# SN32F290 register map
Vendor: SONIX; File version: 2026.10.03
CPU: CM0 r0p0, little endian, no MPU, no FPU, 2 interrupt priority bits
Registers are 32-bit, read-write, reset 0x0 unless marked. A register's access mark holds for its fields unless they carry their own. Offsets are from the block's base; [hi:lo] are bit positions; {n}, {i} and the like mark numbered series; 'fields as' and 'values as' point back to an identical list.

## SN_USB — Universal Serial Bus Full Speed Device Interface (USB)
Base 0x4005C000
0x00 INTEN (reset mask 0xF0000007F) — Offset:0x00 USB Interrupt Enable Register
  [62:31] BUS_IE — Bus Event Interrupt Enable
    0=Disable_434 (Disable BUS event interrupt); 1=Enable_145 (Enable Bus event interrupt)
  [60:30] USB_SOF_IE — USB SOF Interrupt Enable
    0=Disable_434 (Disable USB SOF interrupt); 1=Enable_145 (Enable USB SOF interrupt)
  [58:29] USB_IE — USB Event Interrupt Enable
    0=Disable_434 (Disable USB event interrupt); 1=Enable_145 (Enable USB event interrupt)
  [56:28] BUSWK_IE — USB Bus Wake Up Interrupt Enable
    0=Disable_434 (Disable Wake Up event interrupt); 1=Enable_145 (Enable Wake Up event interrupt)
  [12:6] EPN_ACK_EN — EPN ACK Interrupt Enable
    0=Disable_434 (Disable EP1~4 ACK interrupt function); 1=Enable_145 (Enable EP1~4 ACK interrupt function)
  [2n-2:n-1] EP{n}_NAK_EN (n=2..6) — EP{n} NAK Interrupt Enable
    0=Disable_434 (Disable EP{n} NAK interrupt function); 1=Enable_145 (Enable EP{n} NAK interrupt function)
  [0] EP1_NAK_EN — EP1 NAK Interrupt Enable
    0=Disable_434 (Disable EP1 NAK interrupt function); 1=Enable_145 (Enable EP1 NAK interrupt function)
0x04 INSTS ro (reset mask 0xE7FE3F3F) — Offset:0x04 USB Interrupt Event Status Register
  [62:31] BUS_RESET — USB Bus Reset signal flag
    0=V_0_164 (No bus reset signal is detected); 1=V_1_374 (Bus reset signal is detected)
  [60:30] BUS_SUSPEND — USB Bus Suspend signal flag
    0=V_0_164 (No bus suspend is detected); 1=V_1_374 (Bus suspend is detected)
  [58:29] BUS_RESUME — USB Bus Resume signal flag
    0=V_0_164 (No bus resume signal is detected); 1=V_1_374 (Bus resume signal from suspend mode is detected)
  [52:26] USB_SOF — USB SOF packet received flag
    0=V_0_164 (No USB SOF packet); 1=V_1_374 (USB SOF packet is received)
  [50:25] BUS_WAKEUP — Bus Wakeup Flag
    0=V_0_164 (No wakeup from suspend mode); 1=V_1_374 (Wakeup from suspend mode)
  [48:24] EP0_PRESETUP — EP0 Setup Token Packet Flag
    0=V_0_164 (No EP0 Setup token packet); 1=V_1_374 (EP0 Setup token packet is received)
  [46:23] EP0_SETUP — EP0 Setup Transaction Flag
    0=V_0_164 (No EP0 Setup transaction); 1=V_1_374 (EP0 Setup transaction is completed)
  [44:22] EP0_IN — EP0 IN ACK Transaction Flag
    0=V_0_164 (No EP0 IN Transaction); 1=V_1_374 (EP0 IN Transaction is completed)
  [42:21] EP0_OUT — EP0 OUT ACK Transaction Flag
    0=V_0_164 (No EP0 OUT ACK transaction); 1=V_1_374 (EP0 OUT ACK transaction is completed)
  [40:20] EP0_IN_STALL — EP0 IN STALL Transaction is completed
    0=V_0_164 (No EP0 IN STALL transaction); 1=V_1_374 (EP0 IN STALL transaction is completed)
  [38:19] EP0_OUT_STALL — EP0 OUT STALL transaction
    0=V_0_164 (No EP0 OUT STALL transaction); 1=V_1_374 (EP0 OUT STALL transaction is completed)
  [36:18] ERR_SETUP — Wrong Setup data received
    0=V_0_164 (Normal 8-byte Setup DATA0 is received); 1=V_1_374 (Setup data is not 8-byte or is not DATA0)
  [34:17] ERR_TIMEOUT — Timeout Status
    0=V_0_164 (No time out); 1=V_1_374 (Bus no any response more than 18 bits time)
  [2n+14:n+7] EP{n}_ACK (n=1..6) — Endpoint {n} ACK transaction flag
    0=V_0_164 (No EP{n} ACK transacation); 1=V_1_374 (EP{n} ACK transaction completes)
  [2n-2:n-1] EP{n}_NAK (n=2..6) — Endpoint {n} NAK transaction flag
    0=V_0_164 (No EP{n} NAK transacation); 1=V_1_374 (EP{n} NAK transaction completes)
  [0] EP1_NAK — Endpoint 1 NAK transaction flag
    0=V_0_164 (No EP1 NAK transacation); 1=V_1_374 (EP1 NAK transaction completes)
0x08 INSTSC wo (reset mask 0xA7FE3F3F) — Offset:0x08 USB Interrupt Event Status Clear Register
  [62:31] BUS_RESETC — USB Bus Reset clear bit
    0=No_effect_200; 1=Clear_V_150 (Clear BUS_RESET bit)
  [58:29] BUS_RESUMEC — USB Bus Resume clear bit
    0=No_effect_200; 1=Clear_V_150 (Clear BUS_RESUME bit)
  [52:26] USB_SOFC — USB SOF clear bit
    0=No_effect_200; 1=Clear_V_150 (Clear USB_SOF bit)
  [50:25] BUS_WAKEUPC — Bus Wakeup clear bit
    0=No_effect_200; 1=Clear_V_150 (Clear BUS_WAKEUP bit)
  [48:24] EP0_PRESETUPC — EP0 PRESETUP clear bit
    0=No_effect_200; 1=Clear_V_150 (Clear EP0_PRESETUP bit)
  [46:23] EP0_SETUPC — EP0 SETUP clear bit
    0=No_effect_200; 1=Clear_V_150 (Clear EP0_SETUP bit)
  [44:22] EP0_INC — EP0 IN clear bit
    0=No_effect_200; 1=Clear_V_150 (Clear EP0_IN bit)
  [42:21] EP0_OUTC — EP0 OUT clear bit
    0=No_effect_200; 1=Clear_V_150 (Clear EP0_OUT bit)
  [40:20] EP0_IN_STALLC — EP0 IN STALL clear bit
    0=No_effect_200; 1=Clear_V_150 (Clear EP0_IN_STALL bit)
  [38:19] EP0_OUT_STALLC — EP0 OUT STALL clear bit
    0=No_effect_200; 1=Clear_V_150 (Clear EP0_OUT_STALL bit)
  [36:18] ERR_SETUPC — Error Setup clear bit
    0=No_effect_200; 1=Clear_V_150 (Clear ERR_SETUP bit)
  [34:17] ERR_TIMEOUTC — Timeout Error clear bit
    0=No_effect_200; 1=Clear_V_150 (Clear ERR_TIMEOUT bit)
  [2n+14:n+7] EP{n}_ACKC (n=1..6) — EP{n} ACK clear bit
    0=No_effect_200; 1=Clear_V_150 (Clear EP{n}_ACK bit)
  [2n-2:n-1] EP{n}_NAKC (n=2..6) — EP{n} NAK clear bit
    0=No_effect_200; 1=Clear_V_150 (Clear EP{n}_NAK bit)
  [0] EP1_NAKC — EP1 NAK clear bit
    0=No_effect_200; 1=Clear_V_150 (Clear EP1_NAK bit)
0x0C ADDR — Offset:0x0C USB Device Address Register
  [6:0] UADDR — USB device's address
0x10 CFG (reset mask 0xFC00003F) — Offset:0x10 USB Configuration Register
  [62:31] VREG33_EN — Enable the internal VREG33 ouput
    0=Disable_434 (Disable VREG33 ouput); 1=Enable_145 (Enable VREG33 ouput)
  [60:30] PHY_EN — PHY Transceiver Function Enable
    0=Disable_434 (Disable PHY transceiver function); 1=Enable_145 (Enable PHY transceiver function)
  [58:29] DPPU_EN — Enable internal D+ 1.5k pull-up resistor
    0=Disable_434 (Disable internal D+ pull-up resistor); 1=Enable_145 (Enable internal D+ pull-up resistor)
  [56:28] SIE_EN — USB Serial Interface Engine Enable
    0=Disable_434 (Disable USB SIE function); 1=Enable_145 (Enable USB SIE function)
  [54:27] ESD_EN — Enable USB anti-ESD protection
    0=Disable_434 (Disable anti-ESD protection); 1=Enable_145 (Enable anti-ESD protection)
  [52:26] DIS_PDEN — Enable internal D+ and D- 175k pull-down resistor
    0=Disable_434; 1=Enable_145
  [2n-2:n-1] EP{n}_DIR (n=2..6) — Endpoint {n} IN/OUT direction setting
    0=IN_6 (EP{n} only handshakes to IN token packet); 1=OUT_2 (EP{n} only handshakes to OUT token packet)
  [0] EP1_DIR — Endpoint 1 IN/OUT direction setting
    0=IN_6 (EP1 only handshakes to IN token packet); 1=OUT_2 (EP1 only handshakes to OUT token packet)
0x14 SGCTL (reset mask 0x7) — Offset:0x14 USB Signal Control Register
  [4:2] BUS_DRVEN — Enable to drive USB bus
    0=Disable_434 (Not to drive USB bus); 1=Enable_145 (Drive USB bus)
  [2:1] BUS_DP — USB DP state
    0=Low_4 (D+ state is low); 1=High_23 (D+ state is high)
  [0] BUS_DN — USB D- state
    0=Low_4 (D- state is low); 1=High_23 (D- state is high)
0x18 EP0CTL (reset mask 0xF800007F) — Offset:0x18 USB Endpoint 0 Control Register
  [62:31] ENDP_EN — Enable Endpoint 0 Function
    0=V_0_164 (Disable); 1=V_1_374 (Enable)
  [59:29] ENDP_STATE — Endpoint Handshake State
    0=V_0_164 (NAK); 1=V_1_374 (ACK); 2=V_2 (INOUT_STALL); 3=V_3_20 (INOUT_STALL)
  [56:28] IN_STALL_EN — Enable EP0 IN STALL handshake
    0=V_0_164 (Disable); 1=V_1_374 (Enable)
  [54:27] OUT_STALL_EN — Enable EP0 OUT STALL handshake
    0=V_0_164 (Disable); 1=V_1_374 (Enable)
  [6:0] ENDP_CNT — Endpoint byte count
{0x18+4i} EP{i}CTL (reset mask 0xE000007F) (i=1..6) — Offset:{0x18+4i} USB Endpoint {i} Control Register
  [62:31] ENDP_EN — Endpoint {i} Function enable bit
    0=V_0_164 (Disable); 1=V_1_374 (Enable)
  [59:29] ENDP_STATE — Endpoint Handshake State
    0=V_0_164 (NAK); 1=V_1_374 (ACK); 2=V_2 (STALL); 3=V_3_20 (STALL)
  [6:0] ENDP_CNT — Endpoint byte count
0x3C EPTOGGLE reset 0xF (reset mask 0x3F) — Offset:0x3C USB Endpoint Data Toggle Register
  [2n-2:n-1] ENDP{n}_DATA01 (n=2..6) — Endpoint {n} data toggle bit
    0=Disable_434 (Clear EP{n} toggle bit to DATA0); 1=Toggle_4 (HW sets toggle bit automatically)
  [0] ENDP1_DATA01 — Endpoint 1 data toggle bit
    0=Disable_434 (Clear EP1 toggle bit to DATA0); 1=Toggle_4 (HW sets toggle bit automatically)
{0x44+4i} EP{i}BUFOS (reset mask 0x1FC) (i=1..6) — Offset:{0x44+4i} USB Endpoint {i} Buffer Offset Register
  [10:2] OFFSET — The offset address for endpoint data buffer
0x60 FRMNO ro — Offset:0x60 USB Frame Number Register
  [10:0] FRAME_NO — The 11-bit frame number of the SOF packet
0x64 PHYPRM (reset mask 0xFC000007) — Offset:0x64 USB PHY Parameter Register
  [5:0] PHY_PARAM — USB PHY parameter
0x6C PHYPRM2 reset 0x400 — Offset:0x6C USB PHY Parameter Register 2
  [14:0] PHY_PS — USB PHY parameter 2
0x70 PS2CTL (reset mask 0x8000000F) — Offset:0x70 PS/2 Control Register
  [all] fields
    0=Disable_434; 1=Enable_145 (Enabled)
  [62:31] PS2ENB — PS/2 internal 5k ohm pull-up resistor control bit
  [6:3] SDA — PS/2 SDA data buffer
  [4:2] SCK — PS/2 SCK data buffer
  [2:1] SDAM — PS/2 SDA mode control bit
  [0] SCKM — PS/2 SCK mode control bit
0x78 RWADDR (reset mask 0xFC) — Offset:0x78 USB Read/Write Address Register
  [9:2] RWADDR — USB FIFO address to be read or written from/to USB FIFO
0x7C RWDATA — Offset:0x7C USB Read/Write Data Register
  [31:0] RWDATA — Data to be read or written from/to USB FIFO
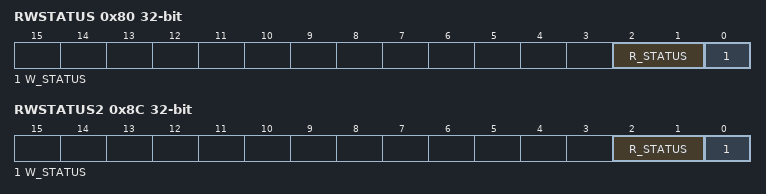
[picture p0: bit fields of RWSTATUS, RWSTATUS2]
0x80 RWSTATUS (reset mask 0x3) — Offset:0x80 USB Read/Write Status Register
  [2:1] R_STATUS — WRead status of USB FIFO
    0=operation_ready_3 (this bit is automatically cleared as '0' by hardware); 1=not_ready_4 (If F/W is to read the data from USB FIFO now)
  [0] W_STATUS — Write status of USB FIFO
    0=operation_ready_3 (this bit is automatically cleared as '0' by hardware); 1=not_ready_4 (F/W is to write data into USB FIFO now)
0x84 RWADDR2 (reset mask 0xFC) — Offset:0x84 USB Read/Write Address Register 2
  fields as RWADDR
0x88 RWDATA2 — Offset:0x88 USB Read/Write Data Register 2
  [31:0] RWDATA — Data to be read or written from/to USB FIFO
0x8C RWSTATUS2 (reset mask 0x3) — Offset:0x8C USB Read/Write Status Register 2
  fields as RWSTATUS
